# STM32H5F5 register map
File version: 1.0
CPU: CM33 r0p0, little endian, MPU, FPU, 4 interrupt priority bits
Registers are 32-bit, read-write, reset 0x0 unless marked. A register's access mark holds for its fields unless they carry their own. Offsets are from the block's base; [hi:lo] are bit positions; {n}, {i} and the like mark numbered series; 'fields as' and 'values as' point back to an identical list.

## DMA2D — DMA2D address block description
Base 0x4002A000
Same registers: DMA2D_S 0x5002A000
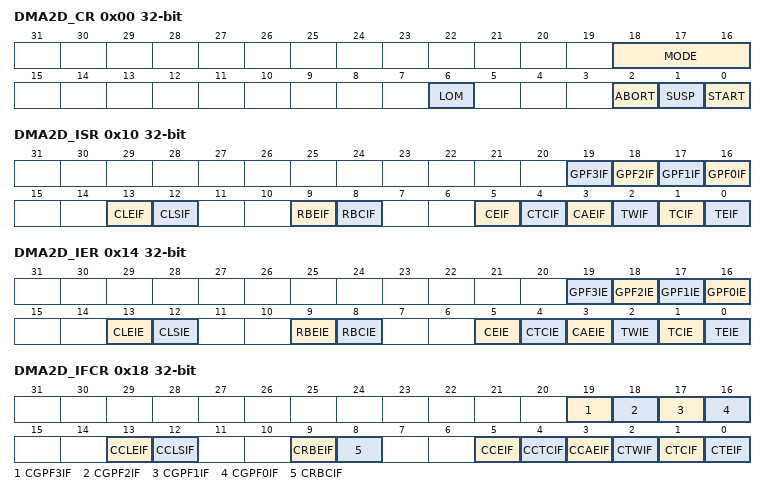
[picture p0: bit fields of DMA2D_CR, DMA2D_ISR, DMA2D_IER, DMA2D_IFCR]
0x00 DMA2D_CR — DMA2D control register
  [18:16] MODE — DMA2D mode
    0=Memory-to-memory (FG fetch only); 1=Memory-to-memory with PFC (FG fetch only with FG PFC active); 2=Memory-to-memory with blending (FG and BG fetch with PFC and blending); 3=Register-to-memory (no FG nor BG, only output stage active); 4=Memory-to-memory with blending and fixed color FG (BG fetch only with FG and BGPFC active); 5=Memory-to-memory with blending and fixed color BG (FG fetch only with FG and BGPFC active)
  [6] LOM — Line offset mode
    0=Line offsets expressed in pixels; 1=Line offsets expressed in bytes
  [2] ABORT
    0=No transfer abort requested; 1=Transfer abort requested
  [1] SUSP — Suspend
    0=Transfer not suspended; 1=Transfer suspended
  [0] START
    0=No DMA2D data transfer on going; 1=DMA2D data transfer on going
0x10 DMA2D_ISR ro — DMA2D interrupt status register
  [n+16] GPF{n}IF (n=0..3) — General purpose flag {n} interrupt flag
    0=No general purpose flag {n} event detected; 1=General purpose flag {n} event detected
  [13] CLEIF — Command list error interrupt flag
    0=No error detected during the command list execution; 1=An error has been detected during the command list execution
  [12] CLSIF — Command list suspended interrupt flag
    0=Command list not suspended; 1=Command list execution has been suspended
  [9] RBEIF — Ring buffer error interrupt flag
    0=No error detected during the ring buffer execution; 1=An error has been detected during the ring buffer execution
  [8] RBCIF — Ring buffer completed interrupt flag
    0=Ring buffer execution not yet completed; 1=Ring buffer execution complete
  [5] CEIF — Configuration error interrupt flag
    0=No configuration error detected; 1=A configuration error has been detected
  [4] CTCIF — CLUT transfer complete interrupt flag
    0=CLUT transfer not yet complete; 1=CLUT transfer complete
  [3] CAEIF — CLUT access error interrupt flag
    0=No CLUT access error detected; 1=CLUT transfer error detected
  [2] TWIF — Transfer watermark interrupt flag
    0=Transfer watermark not yet reached; 1=Transfer watermark reached
  [1] TCIF — Transfer complete interrupt flag
    0=DMA2D data transfer not yet complete; 1=DMA2D data transfer transfer complete
  [0] TEIF — Transfer error interrupt flag
    0=No DMA2D transfer error detected; 1=DMA2D transfer error detected
0x14 DMA2D_IER — DMA2D interrupt enable register
  [n+16] GPF{n}IE (n=0..3) — General purpose flag {n} interrupt enable
    0=GP flag {n} interrupt is disabled; 1=GP flag {n} interrupt is enabled
  [13] CLEIE — Command list error interrupt enable
    0=Command list error interrupt is disabled; 1=Command list error interrupt is enabled
  [12] CLSIE — Command list suspended interrupt enable
    0=Command list suspended interrupt is disabled; 1=Command list suspended interrupt is enabled
  [9] RBEIE — Ring buffer error interrupt enable
    0=Ring buffer error interrupt is disabled; 1=Ring buffer error interrupt is enabled
  [8] RBCIE — Ring buffer completed interrupt enable
    0=Ring buffer completed interrupt is disabled; 1=Ring buffer completed interrupt is enabled
  [5] CEIE — Configuration error interrupt enable
    0=Configuration error interrupt is disabled; 1=Configuration error interrupt is enabled
  [4] CTCIE — CLUT transfer complete interrupt enable
    0=CLUT transfer complete interrupt is disabled; 1=CLUT transfer complete interrupt is enabled
  [3] CAEIE — CLUT access error interrupt enable
    0=CLUT access error interrupt is disabled; 1=CLUT access error interrupt is enabled
  [2] TWIE — Transfer watermark interrupt enable
    0=Transfer watermark interrupt is disabled; 1=Transfer watermark interrupt is enabled
  [1] TCIE — Transfer complete interrupt enable
    0=Transfer complete interrupt is disabled; 1=Transfer complete interrupt is enabled
  [0] TEIE — Transfer error interrupt enable
    0=Transfer error interrupt is disabled; 1=Transfer error interrupt is enabled
0x18 DMA2D_IFCR — DMA2D interrupt flag clear register
  [19] CGPF3IF wo — Clear general purpose flag 3 interrupt flag
    0=Do nothing; 1=Clear GPF3IF flag in DMA2D_ISR
  [18] CGPF2IF wo — Clear general purpose flag 2 interrupt flag
    0=Do nothing; 1=Clear GPF2IF flag in DMA2D_ISR
  [17] CGPF1IF wo — Clear general purpose flag 1interrupt flag
    0=Do nothing; 1=Clear GPF2IF flag in DMA2D_ISR
  [16] CGPF0IF ro — Clear general purpose flag 0 interrupt flag
    0=Do nothing; 1=Clear GPF1IF flag in DMA2D_ISR
  [13] CCLEIF wo — Clear command list error interrupt flag
    0=Do nothing; 1=Clear CLEIF flag in DMA2D_ISR
  [12] CCLSIF wo — Clear command list suspended interrupt flag
    0=Do nothing; 1=Clear CLSIF flag in DMA2D_ISR
  [9] CRBEIF wo — Clear ring buffer error interrupt flag
    0=Do nothing; 1=Clear RBEIF flag in DMA2D_ISR
  [8] CRBCIF wo — Clear ring buffer completed interrupt flag
    0=Do nothing; 1=Clear RBCIF flag in DMA2D_ISR
  [5] CCEIF wo — Clear configuration error interrupt flag
    0=Do nothing; 1=Clear CEIF flag in DMA2D_ISR
  [4] CCTCIF wo — Clear CLUT transfer complete interrupt flag
    0=Do nothing; 1=Clear CTCIF flag in DMA2D_ISR
  [3] CCAEIF wo — Clear CLUT access error interrupt flag
    0=Do nothing; 1=Clear CAEIF flag in DMA2D_ISR
  [2] CTWIF wo — Clear transfer watermark interrupt flag
    0=Do nothing; 1=Clear TWIF flag in DMA2D_ISR
  [1] CTCIF wo — Clear transfer complete interrupt flag
    0=Do nothing; 1=Clear TCIF flag in DMA2D_ISR
  [0] CTEIF wo — Clear transfer error interrupt flag
    0=Do nothing; 1=Clear TEIF flag in DMA2D_ISR
0x40 DMA2D_FGMAR — DMA2D foreground memory address register
  [31:0] MA — Memory address
0x44 DMA2D_FGOR — DMA2D foreground offset register
  [15:0] LO — Line offset
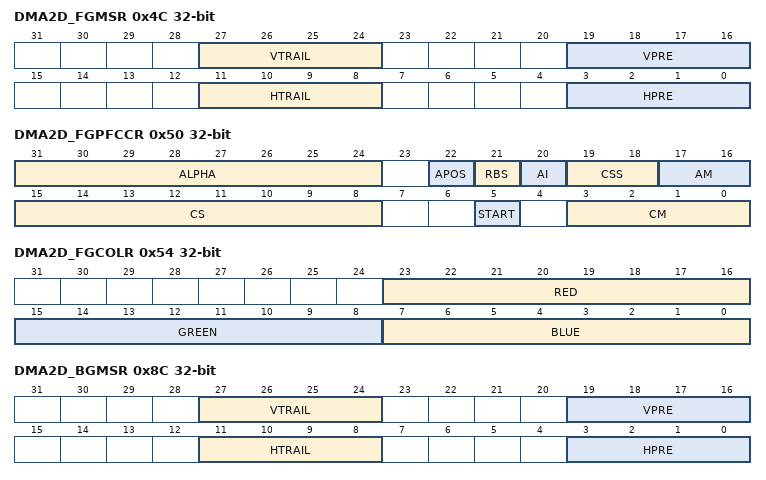
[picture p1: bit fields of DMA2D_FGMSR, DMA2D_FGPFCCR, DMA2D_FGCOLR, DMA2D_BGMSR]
0x4C DMA2D_FGMSR — DMA2D foreground memory skip register
  [27:24] VTRAIL — Vertical trailing lines
  [19:16] VPRE — Vertical pre lines
  [11:8] HTRAIL — Horizontal trailing pixels
  [3:0] HPRE — Horizontal pre pixels
0x50 DMA2D_FGPFCCR — DMA2D foreground PFC control register
  [31:24] ALPHA — Alpha value
  [22] APOS — Alpha position
    0=Regular mode: xRGB or ARGB (default after reset); 1=Swap mode: RGBx or RGBA
  [21] RBS — Red/Blue swap
    0=Regular mode (RGB or ARGB); 1=Swap mode (BGR or ABGR)
  [20] AI — Alpha inverted
    0=Regular alpha; 1=Inverted alpha
  [19:18] CSS — Chroma sub-sampling
    0=4:4:4 (no chroma sub-sampling); 1=4:2:2; 2=4:2:0
  [17:16] AM — Alpha mode
    0=No modification of the layer image alpha channel value; 1=Replace original layer image alpha channel value by ALPHA[7: 0]; 2=Replace original layer image alpha channel value by ALPHA[7:0] multiplied with original alpha channel value
  [15:8] CS — CLUT size
  [5] START
    0=No automatic CLUT loading on going; 1=Automatic CLUT loading on going
  [3:0] CM — Color mode
    0=ARGB8888; 1=RGB888; 2=RGB565; 3=ARGB1555; 4=ARGB4444; 5=L8; 6=AL44; 7=AL88; 8=L4; 9=A8; 10=A4; 11=JPEG; 12=A2; 13=A1; 14=ARGB2222
0x54 DMA2D_FGCOLR — DMA2D foreground color register
  [23:16] RED — Red value for the A1, A2, A4 or A8 mode of the layer image
  [15:8] GREEN — Green value for the A1, A2, A4 or A8 mode of the foreground image
  [7:0] BLUE — Blue value for the A1, A2, A4 or A8 mode of the foreground image
0x58 DMA2D_FGCMAR — DMA2D foreground CLUT memory address register
  [31:0] MA — Memory address
0x80 DMA2D_BGMAR — DMA2D background memory address register
  [31:0] MA — Memory address
0x84 DMA2D_BGOR — DMA2D background offset register
  [15:0] LO — Line offset
0x8C DMA2D_BGMSR — DMA2D background memory skip register
  fields as DMA2D_FGMSR
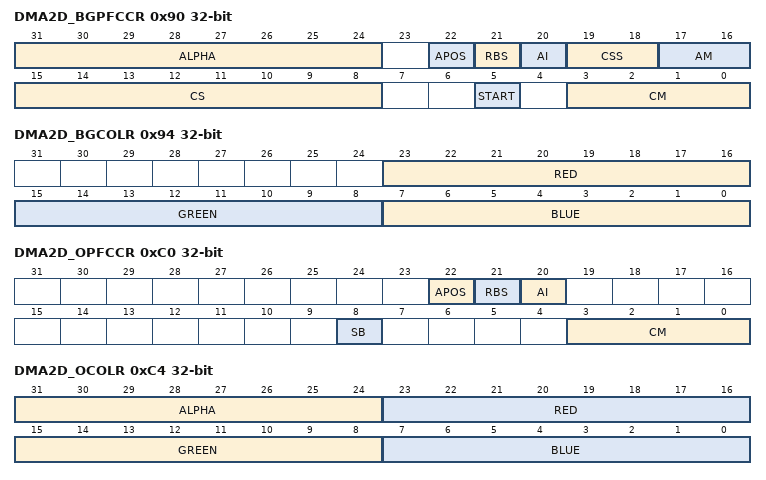
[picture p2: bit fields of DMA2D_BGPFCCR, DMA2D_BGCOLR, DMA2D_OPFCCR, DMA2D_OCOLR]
0x90 DMA2D_BGPFCCR — DMA2D background PFC control register
  [31:24] ALPHA — Alpha value
  [22] APOS — Alpha position
    values as DMA2D_FGPFCCR.APOS
  [21] RBS — Red/Blue swap
    0=Regular mode (RGB or ARGB); 1=Swap mode (BGR or ABGR)
  [20] AI — Alpha inverted
    0=Regular alpha; 1=Inverted alpha
  [19:18] CSS — Chroma sub-sampling
    0=4:4:4 (no chroma subsampling); 1=4:2:2; 2=4:2:0
  [17:16] AM — Alpha mode
    0=No modification of the laeyr image alpha channel value; 1=Replace original layer image alpha channel value by ALPHA[7: 0]; 2=Replace original layer image alpha channel value by ALPHA[7:0] multiplied with original alpha channel value
  [15:8] CS — CLUT size
  [5] START
    values as DMA2D_FGPFCCR.START
  [3:0] CM — Color mode
    values as DMA2D_FGPFCCR.CM
0x94 DMA2D_BGCOLR — DMA2D background color register
  fields as DMA2D_FGCOLR
0x98 DMA2D_BGCMAR — DMA2D background CLUT memory address register
  [31:0] MA — Memory address
0xC0 DMA2D_OPFCCR — DMA2D output PFC control register
  [22] APOS — Alpha position
    values as DMA2D_FGPFCCR.APOS
  [21] RBS — Red/Blue swap
    0=Regular mode (RGB or ARGB); 1=Swap mode (BGR or ABGR)
  [20] AI — Alpha Inverted
    0=Regular alpha; 1=Inverted alpha
  [8] SB — Swap bytes
    0=Bytes in regular order in the output FIFO; 1=Bytes swapped two by two in the output FIFO
  [3:0] CM — Color mode
    0=ARGB8888; 1=RGB888; 2=RGB565; 3=ARGB1555; 4=ARGB4444; 14=ARGB2222
0xC4 DMA2D_OCOLR — DMA2D output color register
  [31:24] ALPHA — Alpha channel value of the output color in ARGB8888 mode (otherwise reserved)
  [23:16] RED — Red value of the output image in ARGB8888 or RGB888 mode
  [15:8] GREEN — Green value of the output image in ARGB8888 or RGB888
  [7:0] BLUE — Blue value of the output image in ARGB8888 or RGB888
0xC8 DMA2D_OMAR — DMA2D output memory address register
  [31:0] MA — Memory address
0xCC DMA2D_OOR — DMA2D output offset register
  [15:0] LO — Line offset
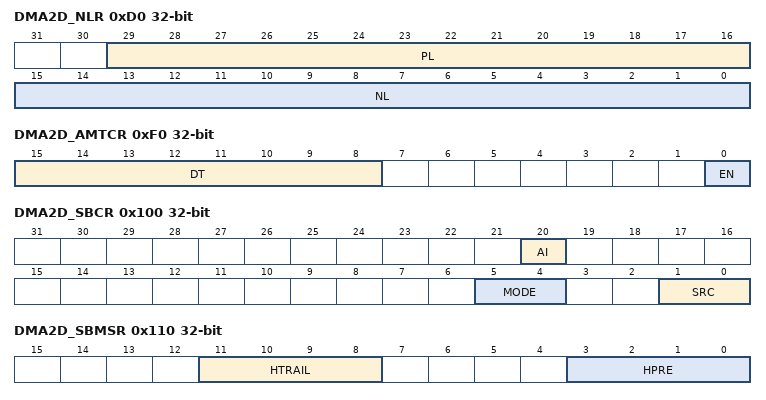
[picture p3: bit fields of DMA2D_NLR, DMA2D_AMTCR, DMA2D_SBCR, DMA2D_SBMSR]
0xD0 DMA2D_NLR — DMA2D number of line register
  [29:16] PL — Pixel per lines
  [15:0] NL — Number of lines
0xE0 DMA2D_LWR — DMA2D line watermark register
  [15:0] LW — Line watermark for interrupt generation
0xF0 DMA2D_AMTCR — DMA2D AHB master timer configuration register
  [15:8] DT — Dead time
  [0] EN — Dead-time functionality enable
0x100 DMA2D_SBCR — DMA2D stencil buffer configuration register
  [20] AI — Alpha Inverted
    0=Regular alpha; 1=Inverted alpha
  [5:4] MODE
    0=1bpp (default after reset); 1=2bpp; 2=4bpp; 3=8bpp
  [1:0] SRC — Source
    0=No stencil buffer (default after reset); 1=Foreground plane; 2=Background plane; 3=Blender output
0x104 DMA2D_SBMAR — DMA2D stencil buffer memory address register
  [31:0] MA — Memory address, address of the data used for the stencil buffer
0x108 DMA2D_SBOR — DMA2D stencil buffer offset register
  [15:0] LO — Line offset
0x110 DMA2D_SBMSR — DMA2D stencil buffer memory skip register
  [11:8] HTRAIL — Horizontal trailing pixels
  [3:0] HPRE — Horizontal pre pixels
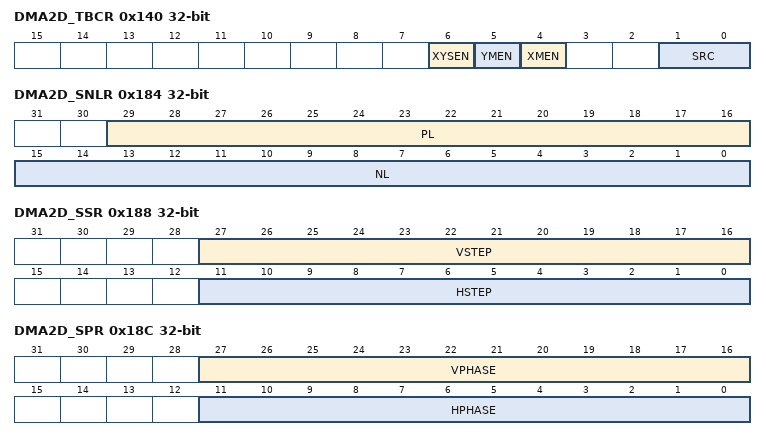
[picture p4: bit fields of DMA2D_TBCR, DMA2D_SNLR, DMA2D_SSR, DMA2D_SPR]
0x140 DMA2D_TBCR — DMA2D tile buffer configuration register
  [6] XYSEN — X/Y swap enable
    0=X/Y not swapped (default after reset); 1=X/Y swapped
  [5] YMEN — Y mirroring enable
    0=Y not mirrored (default after reset); 1=Y mirrored
  [4] XMEN — X mirroring enable
    0=X not mirrored (default after reset); 1=X mirrored
  [1:0] SRC — Source
    0=No tile buffer (default after reset); 1=Foreground plane; 2=Background plane; 3=Blender output
0x180 DMA2D_SCR — DMA2D scaler configuration register
  [1:0] SRC — Source
    0=scaler is disabled (default after reset); 1=Foreground plane; 2=Background plane; 3=Blender output
0x184 DMA2D_SNLR — DMA2D scaler number of line register
  [29:16] PL — Pixel per lines
  [15:0] NL — Number of lines
0x188 DMA2D_SSR — DMA2D scaler step register
  [27:16] VSTEP — vertical step
  [11:0] HSTEP — horizontal step
0x18C DMA2D_SPR — DMA2D scaler phase register
  [27:16] VPHASE — vertical phase
  [11:0] HPHASE — horizontal phase
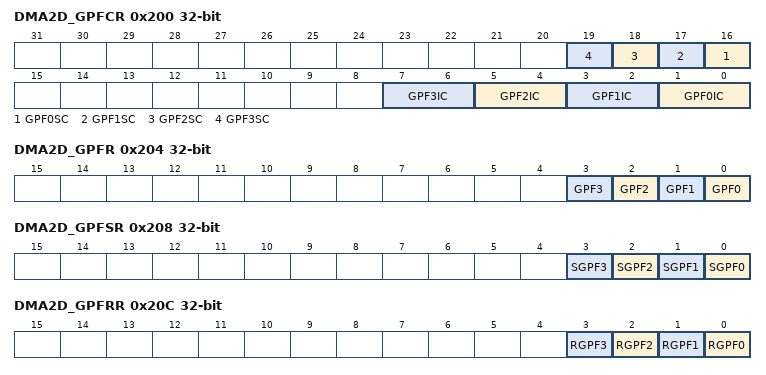
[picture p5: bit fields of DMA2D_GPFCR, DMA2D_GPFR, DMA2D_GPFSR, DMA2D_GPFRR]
0x200 DMA2D_GPFCR — DMA2D general purpose flag configuration register
  [n+16] GPF{n}SC (n=0..3) — General purpose flag {n} suspend configuration
    0=no effect; 1=the command list execution is suspended when GPF{n} is set
  [2n+1:2n] GPF{n}IC (n=0..3) — General purpose flag {n} interrupt configuration
    0=GPIF{n} is never set; 1=GPIF{n} is set on a rising edge of the GPF{n}; 2=GPIF{n} is set on a falling edge of the GPF{n}; 3=GPIF{n} is set on a rising or a falling edge of the GPF{n}
0x204 DMA2D_GPFR ro — DMA2D general purpose flag register
  [n] GPF{n} (n=0..3) — General purpose flag {n}
    0=GPF{n} is reset; 1=GPF{n} is set
0x208 DMA2D_GPFSR wo — DMA2D general purpose flag set register
  [n] SGPF{n} (n=0..3) — Set general purpose flag {n}
    0=no effect; 1=set GPF{n}
0x20C DMA2D_GPFRR wo — DMA2D general purpose flag reset register
  [n] RGPF{n} (n=0..3) — Reset general purpose flag {n}
    0=no effect; 1=reset GPF{n}
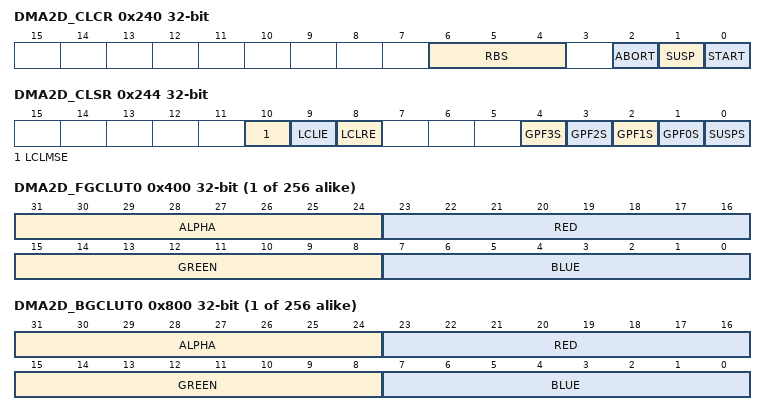
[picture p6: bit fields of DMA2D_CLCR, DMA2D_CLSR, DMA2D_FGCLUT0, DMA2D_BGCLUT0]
0x240 DMA2D_CLCR — DMA2D command list configuration register
  [6:4] RBS — Ring buffer size
  [2] ABORT
    0=No command list execution abort requested; 1=Command list execution abort requested
  [1] SUSP — Suspend
    0=No command list execution suspension request; 1=Command list execution suspension requested
  [0] START
    0=No ring buffer execution on going; 1=Ring buffer execution on going
0x244 DMA2D_CLSR ro — DMA2D command list status register
  [10] LCLMSE — Linear command list multiple start error
    0=no error; 1=Linear command list multi start error occurred
  [9] LCLIE — Linear command list instruction error
    0=no error; 1=Linear command list end mismatch/illegal instruction error occurred
  [8] LCLRE — Linear command list read error
    0=no error; 1=Linear command list read error occurred
  [n+1] GPF{n}S (n=0..3) — General purpose flag {n} suspend
    0=the command list is not suspended; 1=the command list is suspended by general purpose flag {n}
  [0] SUSPS — SUSP bit suspend
    0=the command list is not suspended; 1=the command list is suspended by the SUSP bit
0x250 DMA2D_RBBAR — DMA2D ring buffer base address register
  [31:0] ADDRESS
0x254 DMA2D_RBHPR — DMA2D ring buffer head pointer register
  [13:0] HP — Head Pointer
0x258 DMA2D_RBWPR — DMA2D ring buffer write pointer register
  [13:0] WP — Write Pointer
0x260 DMA2D_LBCBAR ro — DMA2D linear buffer current base address register
  [31:0] ADDRESS
0x264 DMA2D_LBCSR ro — DMA2D linear buffer current size register
  [11:0] SIZE
0x268 DMA2D_LBCAR ro — DMA2D linear buffer current address register
  [31:0] ADDRESS
{0x400+4i} DMA2D_FGCLUT{i} reset not defined (i=0..255) — DMA2D foreground CLUT{i}
  [31:24] ALPHA, [23:16] RED, [15:8] GREEN, [7:0] BLUE
{0x800+4i} DMA2D_BGCLUT{i} reset not defined (i=0..255) — DMA2D background CLUT{i}
  [31:24] ALPHA, [23:16] RED, [15:8] GREEN, [7:0] BLUE
